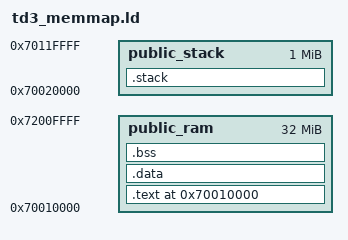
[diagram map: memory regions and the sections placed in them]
/* 
    Definiciones necesarias: formato de salida, arquitectura y punto de entrada
*/
OUTPUT_FORMAT("elf32-littlearm")
OUTPUT_ARCH(arm)
ENTRY(_reset_vector)


/* 
    Definiciones de simbolos necesarios
*/
_ISR_TABLE_START = 0x00000000;
_PUBLIC_RAM_INIT = 0x70010000;
_PUBLIC_STACK_INIT = 0x70020000;

C_STACK_SIZE   = 4K;
IRQ_STACK_SIZE = 128;
FIQ_STACK_SIZE = 128;
SVC_STACK_SIZE = 128;
ABT_STACK_SIZE = 128;
UND_STACK_SIZE = 128;

/* 
    Definición del mapa de memoria
*/
MEMORY
{
    public_ram	: org = _PUBLIC_RAM_INIT, len = 32M
    public_stack : org = _PUBLIC_STACK_INIT, len = 1M
}

/* 
    Definición de las secciones
*/
SECTIONS
{   
    __isr_table_start__ = _ISR_TABLE_START;
    . = _PUBLIC_RAM_INIT;
    .text : { 
        *(._reset_vector_code*)
        *(._start_code*)
        *(.text_pub*)
        *(.text*) 
        } > public_ram

    .data : { *(.data*) } > public_ram

    .bss : {
        . = ALIGN(4);
        __bss_start__ = .;
        *(.bss*)
        __bss_end__ = .;
        } > public_ram

    .stack :
        {
        __stack_start__ = .;
        . += IRQ_STACK_SIZE;
        . = ALIGN(4);
        __irq_stack_top__ = .;

        . += FIQ_STACK_SIZE;
        . = ALIGN(4);
        __fiq_stack_top__ = .;

        . += SVC_STACK_SIZE;
        . = ALIGN(4);
        __svc_stack_top__ = .;

        . += ABT_STACK_SIZE;
        . = ALIGN(4);
        __abt_stack_top__ = .;

        . += UND_STACK_SIZE;
        . = ALIGN(4);
        __und_stack_top__ = .;

        . += C_STACK_SIZE;
        . = ALIGN(4);
        __sys_stack_top__ = .;

        __stack_end__ = .;
        } > public_stack

}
